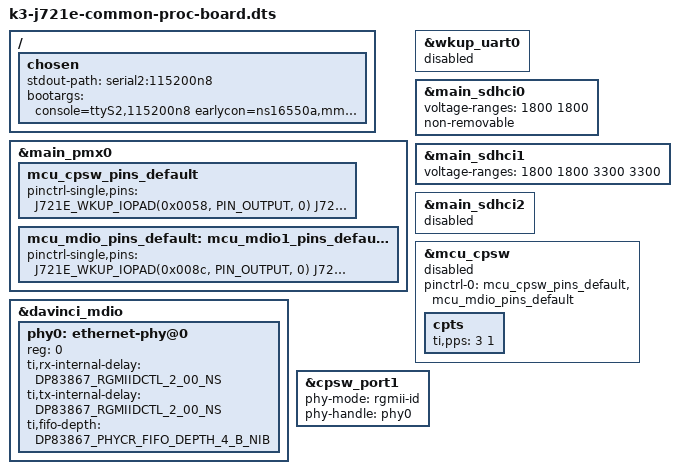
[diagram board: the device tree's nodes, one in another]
// SPDX-License-Identifier: GPL-2.0
/*
 * Copyright (C) 2019 Texas Instruments Incorporated - http://www.ti.com/
 */

/dts-v1/;

#include "k3-j721e-som-p0.dtsi"
#include <dt-bindings/net/ti-dp83867.h>

/ {
	chosen {
		stdout-path = "serial2:115200n8";
		bootargs = "console=ttyS2,115200n8 earlycon=ns16550a,mmio32,0x02800000";
	};
};

&main_pmx0 {
	mcu_cpsw_pins_default: mcu_cpsw_pins_default {
		pinctrl-single,pins = <
			J721E_WKUP_IOPAD(0x0058, PIN_OUTPUT, 0) /* MCU_RGMII1_TX_CTL */
			J721E_WKUP_IOPAD(0x005c, PIN_INPUT, 0) /* MCU_RGMII1_RX_CTL */
			J721E_WKUP_IOPAD(0x0060, PIN_OUTPUT, 0) /* MCU_RGMII1_TD3 */
			J721E_WKUP_IOPAD(0x0064, PIN_OUTPUT, 0) /* MCU_RGMII1_TD2 */
			J721E_WKUP_IOPAD(0x0068, PIN_OUTPUT, 0) /* MCU_RGMII1_TD1 */
			J721E_WKUP_IOPAD(0x006c, PIN_OUTPUT, 0) /* MCU_RGMII1_TD0 */
			J721E_WKUP_IOPAD(0x0078, PIN_INPUT, 0) /* MCU_RGMII1_RD3 */
			J721E_WKUP_IOPAD(0x007c, PIN_INPUT, 0) /* MCU_RGMII1_RD2 */
			J721E_WKUP_IOPAD(0x0080, PIN_INPUT, 0) /* MCU_RGMII1_RD1 */
			J721E_WKUP_IOPAD(0x0084, PIN_INPUT, 0) /* MCU_RGMII1_RD0 */
			J721E_WKUP_IOPAD(0x0070, PIN_INPUT, 0) /* MCU_RGMII1_TXC */
			J721E_WKUP_IOPAD(0x0074, PIN_INPUT, 0) /* MCU_RGMII1_RXC */
		>;
	};

	mcu_mdio_pins_default: mcu_mdio1_pins_default {
		pinctrl-single,pins = <
			J721E_WKUP_IOPAD(0x008c, PIN_OUTPUT, 0) /* MCU_MDIO0_MDC */
			J721E_WKUP_IOPAD(0x0088, PIN_INPUT, 0) /* MCU_MDIO0_MDIO */
		>;
	};
};

&wkup_uart0 {
	/* Wakeup UART is used by System firmware */
	status = "disabled";
};

&main_sdhci0 {
	/* eMMC */
	voltage-ranges = <1800 1800>;
	non-removable;
};

&main_sdhci1 {
	/* SD/MMC */
	voltage-ranges = <1800 1800 3300 3300>;
};

&main_sdhci2 {
	/* Unused */
	status = "disabled";
};

&mcu_cpsw {
	status = "enabled";
	pinctrl-names = "default";
	pinctrl-0 = <&mcu_cpsw_pins_default &mcu_mdio_pins_default>;

	cpts {
		ti,pps = <3 1>;
	};
};

&davinci_mdio {
	phy0: ethernet-phy@0 {
		reg = <0>;
		ti,rx-internal-delay = <DP83867_RGMIIDCTL_2_00_NS>;
		ti,tx-internal-delay = <DP83867_RGMIIDCTL_2_00_NS>;
		ti,fifo-depth = <DP83867_PHYCR_FIFO_DEPTH_4_B_NIB>;
	};
};

&cpsw_port1 {
	phy-mode = "rgmii-id";
	phy-handle = <&phy0>;
};
